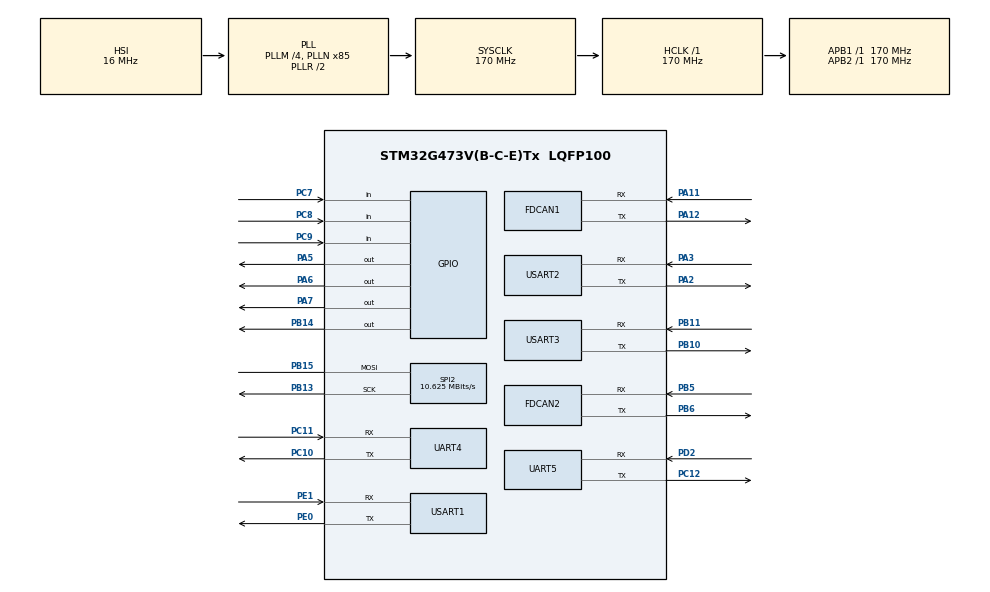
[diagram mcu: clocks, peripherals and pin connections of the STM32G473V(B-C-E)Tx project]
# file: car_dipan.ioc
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FDCAN1.AutoRetransmission=ENABLE
FDCAN1.CalculateBaudRateNominal=3541666
FDCAN1.CalculateTimeBitNominal=282
FDCAN1.CalculateTimeQuantumNominal=94.11764705882354
FDCAN2.AutoRetransmission=ENABLE
FDCAN2.CalculateBaudRateNominal=3541666
FDCAN2.CalculateTimeBitNominal=282
FDCAN2.CalculateTimeQuantumNominal=94.11764705882354
Mcu.Family=STM32G4
Mcu.Name=STM32G473V(B-C-E)Tx
Mcu.Package=LQFP100
NVIC.PriorityGroup=NVIC_PRIORITYGROUP_4
NVIC.UART4_IRQn=true\:0\:0\:false\:false\:true\:true\:true\:true
NVIC.UART5_IRQn=true\:0\:0\:false\:false\:true\:true\:true\:true
NVIC.USART1_IRQn=true\:0\:0\:false\:false\:true\:true\:true\:true
NVIC.USART2_IRQn=true\:0\:0\:false\:false\:true\:true\:true\:true
NVIC.USART3_IRQn=true\:0\:0\:false\:false\:true\:true\:true\:true
PA11.Mode=FDCAN_Activate
PA11.Signal=FDCAN1_RX
PA12.Mode=FDCAN_Activate
PA12.Signal=FDCAN1_TX
PA2.Mode=Asynchronous
PA2.Signal=USART2_TX
PA3.Mode=Asynchronous
PA3.Signal=USART2_RX
PA5.Signal=GPIO_Output
PA6.Signal=GPIO_Output
PA7.Signal=GPIO_Output
PB10.Mode=Asynchronous
PB10.Signal=USART3_TX
PB11.Mode=Asynchronous
PB11.Signal=USART3_RX
PB13.Mode=Simplex_Bidirectional_Master
PB13.Signal=SPI2_SCK
PB14.Signal=GPIO_Output
PB15.Mode=Simplex_Bidirectional_Master
PB15.Signal=SPI2_MOSI
PB5.Mode=FDCAN_Activate
PB5.Signal=FDCAN2_RX
PB6.Mode=FDCAN_Activate
PB6.Signal=FDCAN2_TX
PC10.Mode=Asynchronous
PC10.Signal=UART4_TX
PC11.Mode=Asynchronous
PC11.Signal=UART4_RX
PC12.Mode=Asynchronous
PC12.Signal=UART5_TX
PC7.Signal=GPIO_Input
PC8.Signal=GPIO_Input
PC9.Signal=GPIO_Input
PD2.Mode=Asynchronous
PD2.Signal=UART5_RX
PE0.Mode=Asynchronous
PE0.Signal=USART1_TX
PE1.Mode=Asynchronous
PE1.Signal=USART1_RX
ProjectManager.HeapSize=0x200
ProjectManager.StackSize=0x400
ProjectManager.TargetToolchain=MDK-ARM V5.32
RCC.ADC12Freq_Value=170000000
RCC.ADC345Freq_Value=170000000
RCC.AHBFreq_Value=170000000
RCC.APB1Freq_Value=170000000
RCC.APB1TimFreq_Value=170000000
RCC.APB2Freq_Value=170000000
RCC.APB2TimFreq_Value=170000000
RCC.CortexFreq_Value=170000000
RCC.EXTERNAL_CLOCK_VALUE=12288000
RCC.HCLKFreq_Value=170000000
RCC.HSE_VALUE=8000000
RCC.HSI48_VALUE=48000000
RCC.HSI_VALUE=16000000
RCC.LSE_VALUE=32768
RCC.PLLM=RCC_PLLM_DIV4
RCC.PLLN=85
RCC.SYSCLKFreq_VALUE=170000000
RCC.SYSCLKSource=RCC_SYSCLKSOURCE_PLLCLK
RCC.USBFreq_Value=170000000
RCC.VCOOutputFreq_Value=340000000
SPI2.BaudRatePrescaler=SPI_BAUDRATEPRESCALER_16
SPI2.CLKPhase=SPI_PHASE_2EDGE
SPI2.CLKPolarity=SPI_POLARITY_HIGH
SPI2.CalculateBaudRate=10.625 MBits/s
SPI2.DataSize=SPI_DATASIZE_8BIT
SPI2.Direction=SPI_DIRECTION_1LINE
SPI2.Mode=SPI_MODE_MASTER
SPI2.VirtualType=VM_MASTER
USART1.VirtualMode-Asynchronous=VM_ASYNC
USART2.VirtualMode-Asynchronous=VM_ASYNC
USART3.VirtualMode-Asynchronous=VM_ASYNC
VP_SYS_VS_DBSignals.Mode=DisableDeadBatterySignals
board=custom

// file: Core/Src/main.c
/* USER CODE BEGIN Header */
/**
  ******************************************************************************
  * @file           : main.c
  * @brief          : Main program body
  ******************************************************************************
  * @attention
  *
  * Copyright (c) 2026 STMicroelectronics.
  * All rights reserved.
  *
  * This software is licensed under terms that can be found in the LICENSE file
  * in the root directory of this software component.
  * If no LICENSE file comes with this software, it is provided AS-IS.
  *
  ******************************************************************************
  */
/* USER CODE END Header */
#include "main.h"
#include "fdcan.h"
#include "spi.h"
#include "usart.h"
#include "gpio.h"

/* USER CODE BEGIN Includes */
#include "lcd.h"
#include "app_chassis.h"
/* USER CODE END Includes */

void SystemClock_Config(void);

int main(void)
{

  /* MCU Configuration--------------------------------------------------------*/

  /* Reset of all peripherals, Initializes the Flash interface and the Systick. */
  HAL_Init();

  /* Configure the system clock */
  SystemClock_Config();

  /* Initialize all configured peripherals */
  MX_GPIO_Init();
  MX_USART1_UART_Init();
  MX_SPI2_Init();
  MX_FDCAN1_Init();
  MX_FDCAN2_Init();
  MX_UART4_Init();
  MX_UART5_Init();
  MX_USART2_UART_Init();
  MX_USART3_UART_Init();
  /* USER CODE BEGIN 2 */
  /* 屏幕初始化（ST7789 2.00寸 320x240），并显示一行字 */
  LCD_Init();
  LCD_ShowString(128, 112, "我是G473-1", GREEN, BLACK);

  /* 底盘初始化：CAN + 2×M2006/C610 + 速度环 */
  App_Chassis_Init();
  /* 最简运动示例：前进 0.2 m/s（改 0.0f 即停车，可用示波器/轮子验证方向） */
  App_Chassis_SetVelocity(0.2f, 0.0f);
  /* USER CODE END 2 */

  /* Infinite loop */
  while (1)
  {

    /* USER CODE BEGIN 3 */
    App_Chassis_Task();
  }
  /* USER CODE END 3 */
}

void SystemClock_Config(void)
{
  RCC_OscInitTypeDef RCC_OscInitStruct = {0};
  RCC_ClkInitTypeDef RCC_ClkInitStruct = {0};

  /** Configure the main internal regulator output voltage
  */
  HAL_PWREx_ControlVoltageScaling(PWR_REGULATOR_VOLTAGE_SCALE1_BOOST);

  /** Initializes the RCC Oscillators according to the specified parameters
  * in the RCC_OscInitTypeDef structure.
  */
  RCC_OscInitStruct.OscillatorType = RCC_OSCILLATORTYPE_HSI;
  RCC_OscInitStruct.HSIState = RCC_HSI_ON;
  RCC_OscInitStruct.HSICalibrationValue = RCC_HSICALIBRATION_DEFAULT;
  RCC_OscInitStruct.PLL.PLLState = RCC_PLL_ON;
  RCC_OscInitStruct.PLL.PLLSource = RCC_PLLSOURCE_HSI;
  RCC_OscInitStruct.PLL.PLLM = RCC_PLLM_DIV4;
  RCC_OscInitStruct.PLL.PLLN = 85;
  RCC_OscInitStruct.PLL.PLLP = RCC_PLLP_DIV2;
  RCC_OscInitStruct.PLL.PLLQ = RCC_PLLQ_DIV2;
  RCC_OscInitStruct.PLL.PLLR = RCC_PLLR_DIV2;
  if (HAL_RCC_OscConfig(&RCC_OscInitStruct) != HAL_OK)
  {
    Error_Handler();
  }

  /** Initializes the CPU, AHB and APB buses clocks
  */
  RCC_ClkInitStruct.ClockType = RCC_CLOCKTYPE_HCLK|RCC_CLOCKTYPE_SYSCLK
                              |RCC_CLOCKTYPE_PCLK1|RCC_CLOCKTYPE_PCLK2;
  RCC_ClkInitStruct.SYSCLKSource = RCC_SYSCLKSOURCE_PLLCLK;
  RCC_ClkInitStruct.AHBCLKDivider = RCC_SYSCLK_DIV1;
  RCC_ClkInitStruct.APB1CLKDivider = RCC_HCLK_DIV1;
  RCC_ClkInitStruct.APB2CLKDivider = RCC_HCLK_DIV1;

  if (HAL_RCC_ClockConfig(&RCC_ClkInitStruct, FLASH_LATENCY_4) != HAL_OK)
  {
    Error_Handler();
  }
}

void Error_Handler(void)
{
  __disable_irq();
  while (1)
  {
  }
}
